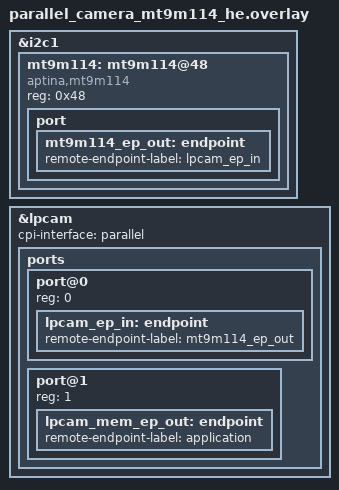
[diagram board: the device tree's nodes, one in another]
/* Copyright (C) 2026 Alif Semiconductor - All Rights Reserved.
 * Use, distribution and modification of this code are permitted under the
 * terms stated in the Alif Semiconductor Software License Agreement.
 *
 * You should have received a copy of the Alif Semiconductor Software
 * License Agreement with this file. If not, please write to:
 * contact@alifsemi.com, or visit: https://alifsemi.com/license
 */

#include <dt-bindings/pinctrl/ensemble-pinctrl.h>
#include <dt-bindings/i2c/i2c.h>
#include <dt-bindings/gpio/gpio.h>

&i2c1 {
	status = "okay";

	mt9m114: mt9m114@48{
		compatible = "aptina,mt9m114";
		reg = <0x48>;
		status = "okay";

		port {
			mt9m114_ep_out: endpoint {
				remote-endpoint-label = "lpcam_ep_in";
			};
		};
	};
};

&lpcam {
	status = "okay";
	cpi-interface = "parallel";
	ports {
		#address-cells = <1>;
		#size-cells = <0>;

		/* Camera Input Endpoint. For LP-CAM it is only camera */
		port@0 {
			reg = <0>;
			lpcam_ep_in: endpoint {
				remote-endpoint-label = "mt9m114_ep_out";
			};
		};

		/* Video buffer output endpoint (Memory). */
		port@1 {
			reg = <1>;
			lpcam_mem_ep_out: endpoint {
				remote-endpoint-label = "application";
			};
		};
	};
};
